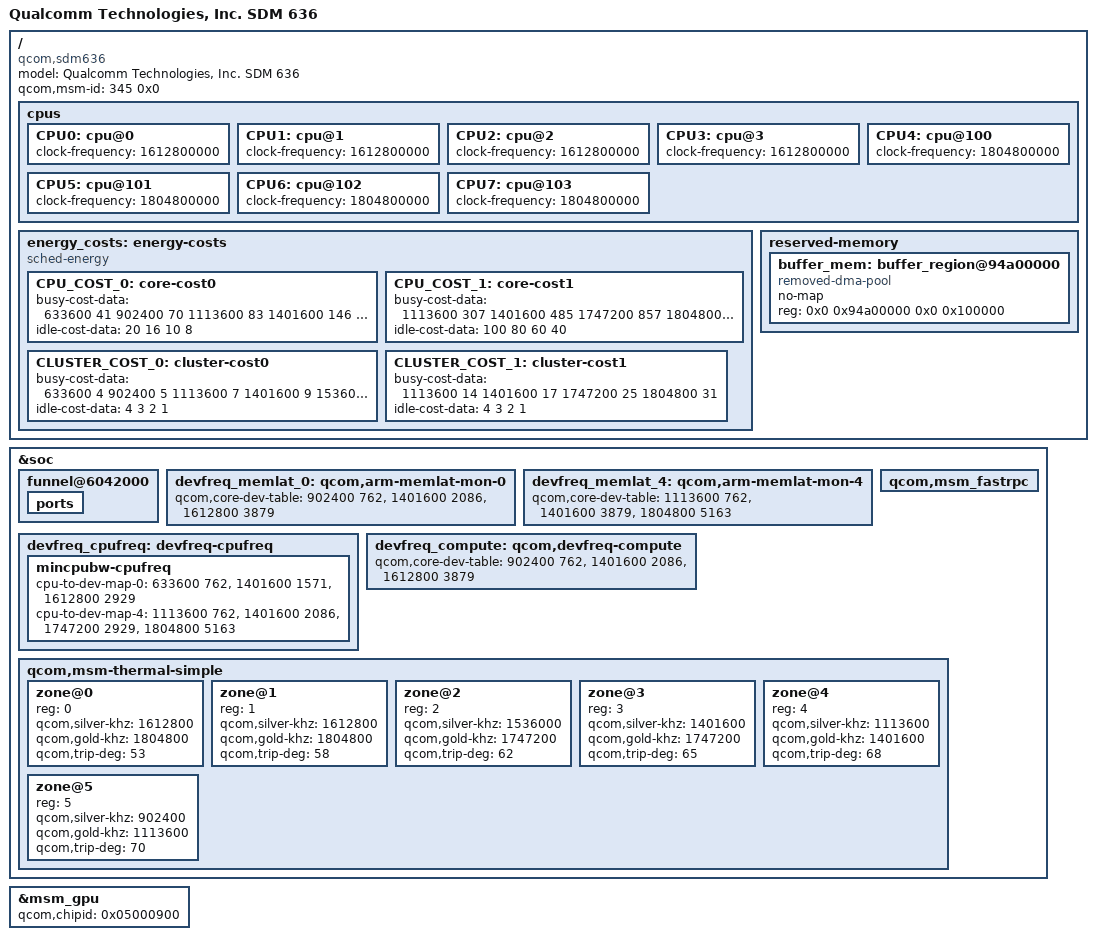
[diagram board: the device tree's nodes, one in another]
/* Copyright (c) 2017-2018, The Linux Foundation. All rights reserved.
 *
 * This program is free software; you can redistribute it and/or modify
 * it under the terms of the GNU General Public License version 2 and
 * only version 2 as published by the Free Software Foundation.
 *
 * This program is distributed in the hope that it will be useful,
 * but WITHOUT ANY WARRANTY; without even the implied warranty of
 * MERCHANTABILITY or FITNESS FOR A PARTICULAR PURPOSE.  See the
 * GNU General Public License for more details.
 */

#include "sdm660.dtsi"

/ {
	model = "Qualcomm Technologies, Inc. SDM 636";
	compatible = "qcom,sdm636";
	qcom,msm-id = <345 0x0>;

	cpus {
		CPU0: cpu@0 {
			clock-frequency = <1612800000>;
		};

		CPU1: cpu@1 {
			clock-frequency = <1612800000>;
		};

		CPU2: cpu@2 {
			clock-frequency = <1612800000>;
		};

		CPU3: cpu@3 {
			clock-frequency = <1612800000>;
		};

		CPU4: cpu@100 {
			clock-frequency = <1804800000>;
		};

		CPU5: cpu@101 {
			clock-frequency = <1804800000>;
		};

		CPU6: cpu@102 {
			clock-frequency = <1804800000>;
		};

		CPU7: cpu@103 {
			clock-frequency = <1804800000>;
		};
	};

	energy_costs: energy-costs {
		compatible = "sched-energy";

		CPU_COST_0: core-cost0 {
			busy-cost-data = <
				633600	41
				902400	70
				1113600	83
				1401600	146
				1536000	158
				1612800	183
			>;
			idle-cost-data = <
				20 16 10 8
			>;
		};

		CPU_COST_1: core-cost1 {
			busy-cost-data = <
				1113600	307
				1401600	485
				1747200	857
				1804800	883
			>;
			idle-cost-data = <
				100 80 60 40
			>;
		};

		CLUSTER_COST_0: cluster-cost0 {
			busy-cost-data = <
				633600	4
				902400	5
				1113600	7
				1401600	9
				1536000	9
				1612800	10
			>;
			idle-cost-data = <
				4 3 2 1
			>;
		};

		CLUSTER_COST_1: cluster-cost1 {
			busy-cost-data = <
				1113600	14
				1401600	17
				1747200	25
				1804800	31
			>;
			idle-cost-data = <
				4 3 2 1
			>;
		};
	};

	reserved-memory {
		/delete-node/ cdsp_fw_region@94a00000;

		buffer_mem: buffer_region@94a00000 {
			compatible = "removed-dma-pool";
			no-map;
			reg = <0x0 0x94a00000 0x0 0x100000>;
		};
	};
};

&soc {
	/delete-node/ qcom,turing@1a300000;

	/delete-node/ qcom,msm-cdsp-loader;
	/delete-node/ cti@7068000;
	/delete-node/ turing_etm0;
	funnel@6042000 {
		ports {
			/delete-node/ port@4;
		};
	};

	devfreq_memlat_0: qcom,arm-memlat-mon-0 {
		qcom,core-dev-table =
			< 902400 762 >,
			< 1401600 2086 >,
			< 1612800 3879 >;
	};

	devfreq_memlat_4: qcom,arm-memlat-mon-4 {
		qcom,core-dev-table =
			< 1113600 762 >,
			< 1401600 3879 >,
			< 1804800 5163 >;
	};

	devfreq_cpufreq: devfreq-cpufreq {
		mincpubw-cpufreq {
			cpu-to-dev-map-0 =
				< 633600 762 >,
				< 1401600 1571 >,
				< 1612800 2929 >;
			cpu-to-dev-map-4 =
				< 1113600 762 >,
				< 1401600 2086 >,
				< 1747200 2929 >,
				< 1804800 5163 >;
		};
	};

	devfreq_compute: qcom,devfreq-compute {
		qcom,core-dev-table =
			< 902400 762 >,
			< 1401600 2086 >,
			< 1612800 3879 >;
	};
};

&soc {
	/delete-node/ arm,smmu-turing_q6@5180000;
	qcom,msm_fastrpc {
		/delete-node/ qcom,msm_fastrpc_compute_cb5;
		/delete-node/ qcom,msm_fastrpc_compute_cb6;
		/delete-node/ qcom,msm_fastrpc_compute_cb7;
		/delete-node/ qcom,msm_fastrpc_compute_cb8;
		/delete-node/ qcom,msm_fastrpc_compute_cb9;
		/delete-node/ qcom,msm_fastrpc_compute_cb10;
		/delete-node/ qcom,msm_fastrpc_compute_cb11;
		/delete-node/ qcom,msm_fastrpc_compute_cb12;
		/delete-node/ qcom,msm_fastrpc_compute_cb13;
	};
};

&soc {
	qcom,msm-thermal-simple {
		zone@0 {
			reg = <0>;
			qcom,silver-khz = <1612800>;
			qcom,gold-khz = <1804800>;
			qcom,trip-deg = <53>;
		};

		zone@1 {
			reg = <1>;
			qcom,silver-khz = <1612800>;
			qcom,gold-khz = <1804800>;
			qcom,trip-deg = <58>;
		};

		zone@2 {
			reg = <2>;
			qcom,silver-khz = <1536000>;
			qcom,gold-khz = <1747200>;
			qcom,trip-deg = <62>;
		};

		zone@3 {
			reg = <3>;
			qcom,silver-khz = <1401600>;
			qcom,gold-khz = <1747200>;
			qcom,trip-deg = <65>;
		};

		zone@4 {
			reg = <4>;
			qcom,silver-khz = <1113600>;
			qcom,gold-khz = <1401600>;
			qcom,trip-deg = <68>;
		};

		zone@5 {
			reg = <5>;
			qcom,silver-khz = <902400>;
			qcom,gold-khz = <1113600>;
			qcom,trip-deg = <70>;
		};
	};
};

/* GPU overrides */
&msm_gpu {
		/* Update GPU chip ID*/
		qcom,chipid = <0x05000900>;
};
